# AVR16DD14 register map
Vendor: Atmel; File version: 1.0
CPU: other r0p0, little endian, no MPU, no FPU, 4 interrupt priority bits
Registers are 8-bit, read-write, reset 0x0 unless marked. A register's access mark holds for its fields unless they carry their own. Offsets are from the block's base; [hi:lo] are bit positions; {n}, {i} and the like mark numbered series; 'fields as' and 'values as' point back to an identical list.

## PORTA — I/O Ports
Base 0x00800400
Same registers: PORTD 0x00800460, PORTF 0x008004A0
0x00 DIR — Data Direction
0x01 DIRSET — Data Direction Set
0x02 DIRCLR — Data Direction Clear
0x03 DIRTGL — Data Direction Toggle
0x04 OUT — Output Value
0x05 OUTSET — Output Value Set
0x06 OUTCLR — Output Value Clear
0x07 OUTTGL — Output Value Toggle
0x08 IN — Input Value
0x09 INTFLAGS — Interrupt Flags
  [7:0] INT — Pin Interrupt Flag
0x0A PORTCTRL — Port Control
  [0] SRL — Slew Rate Limit Enable
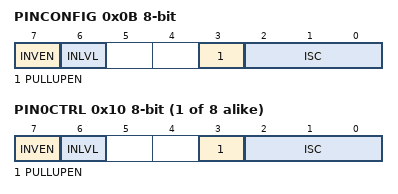
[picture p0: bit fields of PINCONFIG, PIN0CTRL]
0x0B PINCONFIG — Pin Control Config
  [7] INVEN — Inverted I/O Enable
  [6] INLVL — Input level select
  [3] PULLUPEN — Pullup enable
  [2:0] ISC — Input/Sense Configuration
    0=INTDISABLE (Interrupt disabled but input buffer enabled); 1=BOTHEDGES (Sense Both Edges); 2=RISING (Sense Rising Edge); 3=FALLING (Sense Falling Edge); 4=INPUT_DISABLE (Digital Input Buffer disabled); 5=LEVEL (Sense low Level)
0x0C PINCTRLUPD — Pin Control Update
  [7:0] PINCTRLUPD — Pin control update mask
0x0D PINCTRLSET — Pin Control Set
  [7:0] PINCTRLSET — Pin control set mask
0x0E PINCTRLCLR — Pin Control Clear
  [7:0] PINCTRLCLR — Pin control clear mask
{0x10+i} PIN{i}CTRL (i=0..7) — Pin {i} Control
  fields as PINCONFIG

## PORTC — I/O Ports
Base 0x00800440
Registers as PORTA, without PORTCTRL; these are added or differ:
0x0A PORTCTRL — Port Control
  [0] SRL — Slew Rate Limit Enable

## PORTMUX — Port Multiplexer
Base 0x008005E0
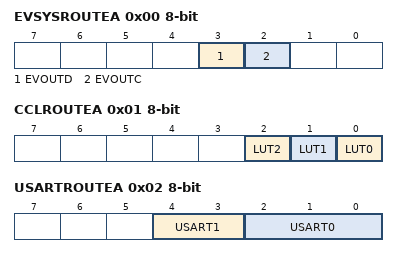
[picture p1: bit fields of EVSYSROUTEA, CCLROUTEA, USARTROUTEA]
0x00 EVSYSROUTEA
  [3] EVOUTD — Event Output D
    0=DEFAULT (Not connected to any pins); 1=ALT1 (EVOUTD: PD7)
  [2] EVOUTC — Event Output C
    0=DEFAULT (EVOUTC: PC2)
0x01 CCLROUTEA
  [2] LUT2 — CCL Look-Up Table 2 Signals
    0=DEFAULT (Not connected to any pins); 1=ALT1 (INn: -, -, -. OUT: PD6.)
  [1] LUT1 — CCL Look-Up Table 1 Signals
    0=DEFAULT (INn: -, PC1, PC2 OUT: PC3); 1=ALT1 (INn: -, PC1, PC2 OUT: -)
  [0] LUT0 — CCL Look-Up Table 0 Signals
    0=DEFAULT (INn: PA0, PA1, -. OUT: -.); 1=ALT1 (INn: PA0, PA1, -. OUT: -.)
0x02 USARTROUTEA
  [4:3] USART1 — USART1 Signals
    0=DEFAULT (TxD: -, RxD: PC1, XCK: PC2, XDIR: PC3); 2=ALT2 (TxD: PD6, RxD: PD7, XCK: -, XDIR: -); 3=NONE (Not connected to any pins)
  [2:0] USART0 — USART0 Signals
    0=DEFAULT (TxD: PA0, RxD: PA1, XCK: -, XDIR: -); 3=ALT3 (TxD: PD4, RxD: PD5, XCK: PD6, XDIR: PD7); 4=ALT4 (TxD: PC1, RxD: PC2, XCK: PC3, XDIR: -); 5=NONE (Not connected to any pins)
0x05 SPIROUTEA
  [2:0] SPI0 — SPI0 Signals
    0=DEFAULT (Not connected to any pins); 3=ALT3 (MOSI: PA0, MISO: PA1, SCK: -, SS: PC1); 4=ALT4 (MOSI: PD4, MISO: PD5, SCK: PD6, SS: PD7); 5=ALT5 (MOSI: -, MISO: PC1, SCK: PC2, SS: PC3); 6=ALT6 (MOSI: PC1, MISO: PC2, SCK: PC3, SS: PF7); 7=NONE (Not connected to any pins. SS set to 1.)
0x06 TWIROUTEA
  [1:0] TWI0 — TWI0 Signals
    0=DEFAULT (SDA: -, SCL: -. Dual mode: SDA: PC2, SCL: PC3.); 2=ALT2 (SDA: PC2, SCL: PC3. Dual mode: SDA: -, SCL: -.); 3=ALT3 (SDA: PA0, SCL: PA1. Dual mode: SDA: PC2, SCL: PC3.)
0x07 TCAROUTEA
  [2:0] TCA0 — TCA0 Signals
    0=PORTA (WOn: PA0, PA1, -, -, -, -); 2=PORTC (WOn: -, PC1, PC2, PC3, -, -); 3=PORTD (WOn: -, -, -, -, PD4, PD5)
0x09 TCDROUTEA
  [2:0] TCD0 — TCD0 Signals
    0=DEFAULT (Not connected to any pins); 4=ALT4 (WOx: -, -, PD4, PD5)

## RSTCTRL — Reset controller
Base 0x00800040
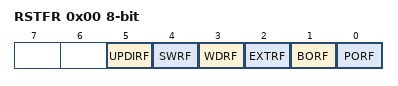
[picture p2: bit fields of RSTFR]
0x00 RSTFR — Reset Flags
  [5] UPDIRF — UPDI Reset flag
  [4] SWRF — Software Reset flag
  [3] WDRF — Watch dog Reset flag
  [2] EXTRF — External Reset flag
  [1] BORF — Brown out detector Reset flag
  [0] PORF — Power on Reset flag
0x01 SWRR — Software Reset
  [0] SWRST — Software reset enable

## RTC — Real-Time Counter
Base 0x00800140
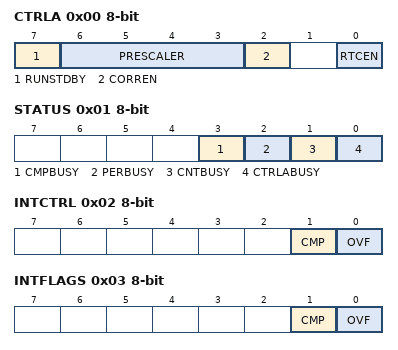
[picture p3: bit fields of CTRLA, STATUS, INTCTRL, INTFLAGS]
0x00 CTRLA — Control A
  [7] RUNSTDBY — Run In Standby
  [6:3] PRESCALER — Prescaling Factor
    0=DIV1 (RTC Clock / 1); 1=DIV2 (RTC Clock / 2); 2=DIV4 (RTC Clock / 4); 3=DIV8 (RTC Clock / 8); 4=DIV16 (RTC Clock / 16); 5=DIV32 (RTC Clock / 32); 6=DIV64 (RTC Clock / 64); 7=DIV128 (RTC Clock / 128); 8=DIV256 (RTC Clock / 256); 9=DIV512 (RTC Clock / 512); 10=DIV1024 (RTC Clock / 1024); 11=DIV2048 (RTC Clock / 2048); 12=DIV4096 (RTC Clock / 4096); 13=DIV8192 (RTC Clock / 8192); 14=DIV16384 (RTC Clock / 16384); 15=DIV32768 (RTC Clock / 32768)
  [2] CORREN — Correction enable
  [0] RTCEN — Enable
0x01 STATUS ro
  [3] CMPBUSY — Comparator Synchronization Busy Flag
  [2] PERBUSY — Period Synchronization Busy Flag
  [1] CNTBUSY — Count Synchronization Busy Flag
  [0] CTRLABUSY — CTRLA Synchronization Busy Flag
0x02 INTCTRL — Interrupt Control
  [1] CMP — Compare Match Interrupt enable
  [0] OVF — Overflow Interrupt enable
0x03 INTFLAGS — Interrupt Flags
  [1] CMP — Compare Match Interrupt
  [0] OVF — Overflow Interrupt Flag
0x04 TEMP — Temporary
0x05 DBGCTRL — Debug control
  [0] DBGRUN — Run in debug
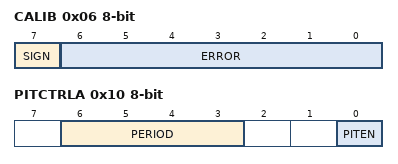
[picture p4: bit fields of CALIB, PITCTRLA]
0x06 CALIB — Calibration
  [7] SIGN — Error Correction Sign Bit
  [6:0] ERROR — Error Correction Value
0x07 CLKSEL — Clock Select
  [1:0] CLKSEL
    0=OSC32K (32.768 kHz from OSC32K); 1=OSC1K (1.024 kHz from OSC32K); 2=XTAL32K (32.768 kHz from XOSC32K); 3=EXTCLK (External Clock)
0x08 CNT 16-bit (reset mask 0xFF) — Counter
0x0A PER 16-bit (reset mask 0xFF) — Period
0x0C CMP 16-bit (reset mask 0xFF) — Compare
0x10 PITCTRLA — PIT Control A
  [6:3] PERIOD
    0=OFF; 1=CYC4 (RTC Clock Cycles 4); 2=CYC8 (RTC Clock Cycles 8); 3=CYC16 (RTC Clock Cycles 16); 4=CYC32 (RTC Clock Cycles 32); 5=CYC64 (RTC Clock Cycles 64); 6=CYC128 (RTC Clock Cycles 128); 7=CYC256 (RTC Clock Cycles 256); 8=CYC512 (RTC Clock Cycles 512); 9=CYC1024 (RTC Clock Cycles 1024); 10=CYC2048 (RTC Clock Cycles 2048); 11=CYC4096 (RTC Clock Cycles 4096); 12=CYC8192 (RTC Clock Cycles 8192); 13=CYC16384 (RTC Clock Cycles 16384); 14=CYC32768 (RTC Clock Cycles 32768)
  [0] PITEN — Enable
0x11 PITSTATUS ro
  [0] CTRLBUSY — CTRLA Synchronization Busy Flag
0x12 PITINTCTRL — PIT Interrupt Control
  [0] PI — Periodic Interrupt
0x13 PITINTFLAGS — PIT Interrupt Flags
  [0] PI — Periodic Interrupt
0x15 PITDBGCTRL — PIT Debug control
  [0] DBGRUN — Run in debug
